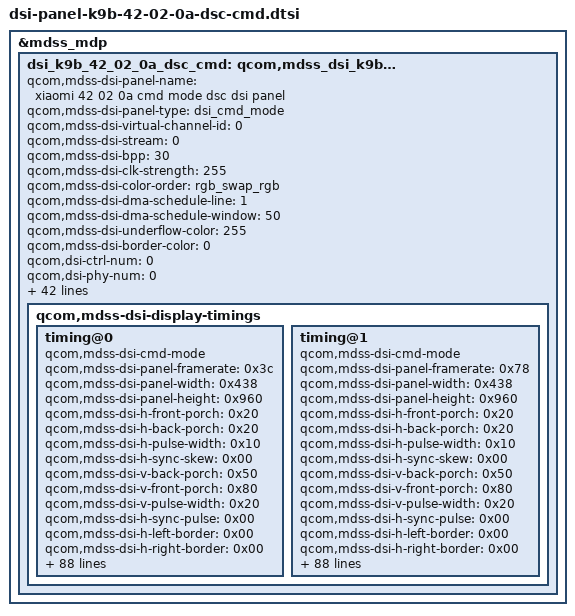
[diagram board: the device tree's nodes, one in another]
&mdss_mdp {
	dsi_k9b_42_02_0a_dsc_cmd: qcom,mdss_dsi_k9b_42_02_0a_dsc_cmd {
		qcom,mdss-dsi-panel-name = "xiaomi 42 02 0a cmd mode dsc dsi panel";
		qcom,mdss-dsi-panel-type = "dsi_cmd_mode";
		qcom,mdss-dsi-virtual-channel-id = <0>;
		qcom,mdss-dsi-stream = <0>;
		qcom,mdss-dsi-bpp = <30>;
		qcom,mdss-dsi-clk-strength = <255>;
		qcom,mdss-dsi-color-order = "rgb_swap_rgb";
		qcom,mdss-dsi-dma-schedule-line = <1>;
		qcom,mdss-dsi-dma-schedule-window = <50>;
		qcom,mdss-dsi-underflow-color = <255>;
		qcom,mdss-dsi-border-color = <0>;

		qcom,dsi-ctrl-num = <0>;
		qcom,dsi-phy-num = <0>;

		qcom,mdss-dsi-traffic-mode = "burst_mode";
		qcom,mdss-dsi-lane-map = "lane_map_0123";
		qcom,mdss-dsi-bllp-eof-power-mode;
		qcom,mdss-dsi-bllp-power-mode;
		qcom,mdss-dsi-lane-0-state;
		qcom,mdss-dsi-lane-1-state;
		qcom,mdss-dsi-lane-2-state;
		qcom,mdss-dsi-lane-3-state;
		qcom,mdss-dsi-dma-trigger = "trigger_sw";
		qcom,mdss-dsi-factory-bl-max-level = <2047>;
		qcom,mdss-dsi-mdp-trigger = "none";
		qcom,mdss-dsi-reset-sequence =  <1 11>, <0 1>, <1 11>;
		qcom,mdss-factory-brightness-max-level = <2047>;
		qcom,mdss-pan-physical-height-dimension = <1517>;
		qcom,mdss-pan-physical-width-dimension = <683>;
		qcom,mdss-dsi-te-pin-select = <1>;
		qcom,mdss-dsi-wr-mem-start = <0x2c>;
		qcom,mdss-dsi-wr-mem-continue = <0x3c>;
		qcom,mdss-dsi-te-dcs-command = <1>;
		qcom,mdss-dsi-te-check-enable;
		qcom,mdss-dsi-te-using-te-pin;
		qcom,mdss-dsi-tx-eot-append;
		qcom,mdss-dsi-lp11-init;

		qcom,mdss-dsi-bl-inverted-dbv;
		qcom,bl-update-flag = "delay_until_first_frame";
		qcom,mdss-dsi-panel-blackness-level = <3230>;
		qcom,mdss-dsi-panel-hdr-color-primaries = <0x38a4 0x3c8c 0x7d00 0x4268 0x3c8c 0x7530 0x1f40 0xbb8>;
		qcom,mdss-dsi-panel-hdr-enabled;
		qcom,mdss-dsi-panel-mode-switch;

		qcom,mdss-dsi-display-timings {
			timing@0{
				qcom,mdss-dsi-cmd-mode;
				qcom,mdss-dsi-panel-framerate = <60>;
				qcom,mdss-dsi-panel-width = <1080>;
				qcom,mdss-dsi-panel-height = <2400>;
				qcom,mdss-dsi-h-front-porch = <32>;
				qcom,mdss-dsi-h-back-porch = <32>;
				qcom,mdss-dsi-h-pulse-width = <16>;
				qcom,mdss-dsi-h-sync-skew = <0>;
				qcom,mdss-dsi-v-back-porch = <8>;
				qcom,mdss-dsi-v-front-porch = <1212>;
				qcom,mdss-dsi-v-pulse-width = <4>;
				qcom,mdss-dsi-h-sync-pulse = <0>;
				qcom,mdss-dsi-h-left-border = <0>;
				qcom,mdss-dsi-h-right-border = <0>;
				qcom,mdss-dsi-v-top-border = <0>;
				qcom,mdss-dsi-v-bottom-border = <0>;
				qcom,mdss-dsi-panel-clockrate = <682000000>;
				qcom,mdss-dsi-panel-jitter = <0x5 0x1>;
				qcom,mdss-mdp-transfer-time-us = <9500>;
				qcom,mdss-dsi-on-command = [
					/* Command Mode */
					39 00 00 00 00 00 06 F0 55 AA 52 08 00
					39 01 00 00 00 00 03 C0 52 F3
					/* ESD/MIPI Error Flag, Low when Error Happen */
					39 00 00 00 00 00 06 F0 55 AA 52 08 00
					39 00 00 00 00 00 05 BE 0E 0B 14 13
					15 00 00 00 00 00 02 6F 05
					15 01 00 00 00 00 02 BE 8A
					/* Round Corner OFF */
					39 00 00 00 00 00 06 F0 55 AA 52 08 07
					39 01 00 00 00 00 03 C0 00 02
					/* VESA ON */
					39 00 00 00 00 00 06 F0 55 AA 52 08 01	// Set page 1
					39 00 00 00 00 00 04 D1 07 00 04
					39 00 00 00 00 00 05 B3 12 12 22 22
					39 00 00 00 00 00 05 B4 12 12 22 22
					15 01 00 00 00 00 02 90 01
					/* Choose VESA Edition */
					39 00 00 00 00 00 13 91
						AB 28 00 0C C2 00 03 1C 01 7E
						00 0F 08 BB 04 3D 10 F0	// DSC Setting
					15 00 00 00 00 00 02 03 01
					39 00 00 00 00 00 05 51 00 00 00 00	// Normal Mode
					15 00 00 00 00 00 02 53 20
					15 00 00 00 00 00 02 35 00	// TE ON
					39 00 00 00 00 00 05 2A 00 00 04 37
					39 00 00 00 00 00 05 2B 00 00 09 5F
					15 01 00 00 00 00 02 2F 02	// 60Hz
					/* OSC=109.2MHz */
					39 00 00 00 00 00 05 FF AA 55 A5 81
					15 00 00 00 00 00 02 6F 0F
					39 01 00 00 00 00 03 FD 01 5A
					/* Demura Gain */
					39 00 00 00 00 00 05 FF AA 55 A5 80
					39 00 00 00 00 00 04 C0 76 F3 C1
					39 00 00 00 00 00 06 F0 55 AA 52 08 04
					15 00 00 00 00 00 02 C2 14
					15 00 00 00 00 00 02 B1 02
					15 00 00 00 00 00 02 B2 40
					15 00 00 00 00 00 02 6F 04
					39 00 00 00 00 00 04 B2 09 E4 00
					15 00 00 00 00 00 02 6F 0A
					39 00 00 00 00 00 04 B2 09 E3 40
					15 00 00 00 00 00 02 CB A4
					39 01 00 00 00 00 05 D0 00 80 00 20
					/* AOD Demura */
					15 00 00 00 00 00 02 B0 01
					39 00 00 00 00 00 06 F0 55 AA 52 08 00
					15 00 00 00 00 00 02 6F 01
					15 01 00 00 00 00 02 C0 B3
					/* AOD Demura End */
					39 00 00 00 00 00 06 F0 55 AA 52 08 04
					15 00 00 00 00 00 02 6F 04
					15 01 00 00 00 00 02 D0 01
					39 00 00 00 00 00 06 F0 55 AA 52 08 00
					15 00 00 00 00 00 02 6F 08
					15 00 00 00 00 00 02 C0 55
					15 01 00 00 00 00 02 8B 10
					39 00 00 00 00 00 06 F0 55 AA 52 08 04
					15 00 00 00 00 00 02 6F 01
					39 01 00 00 00 00 10 CB
						10 20 30 40 80 00 08 00 F6 01
						C2 04 CC 07 FF
					/* 90Hz Gain */
					39 01 00 00 00 00 4C D2
						E0 50 36 2C 27 B0 56 48 34 2E
						A0 60 51 40 32 90 69 59 47 40
						90 73 60 4C 40 E0 50 36 2C 27
						B0 56 48 34 2E A0 60 51 40 32
						90 69 59 47 40 90 73 60 4C 40
						E0 50 36 2C 27 B0 56 48 34 2E
						A0 60 51 40 32 90 69 59 47 40
						90 73 60 4C 40
					/* 60Hz Gain */
					39 01 00 00 00 00 4C D4
						C0 A0 90 90 90 36 39 40 50 60
						25 2C 38 46 5A 24 2B 35 44 48
						13 2A 32 42 42 C0 A0 90 90 90
						36 39 40 50 60 25 2C 38 46 5A
						24 2B 35 44 48 13 2A 32 42 42
						C0 A0 90 90 90 36 39 40 50 60
						25 2C 38 46 5A 24 2B 35 44 48
						13 2A 32 42 42
					/* Demura DC */
					39 01 00 00 00 00 4C D9
						40 40 40 40 40 40 40 40 40 40
						40 40 40 40 40 40 40 40 40 40
						40 40 40 40 40 40 40 40 40 40
						40 40 40 40 40 40 40 40 40 40
						40 40 40 40 40 40 40 40 40 40
						40 40 40 40 40 40 40 40 40 40
						40 40 40 40 40 40 40 40 40 40
						40 40 40 40 40
					/* FCON code */
					39 00 00 00 00 00 06 F0 55 AA 52 08 00
					/* FCON = 1 (90hz) */
					39 00 00 00 00 00 09 BA 01 E9 00 10 00 30 00 01
					/* FCON = 2 (60hz) */
					15 00 00 00 00 00 02 6F 08
					39 00 00 00 00 00 09 BA 01 E9 00 10 04 D0 00 01	// PWM 60&90Hz
					/* FCON = 3 (DC=60hz) */
					15 00 00 00 00 00 02 6F 10
					39 00 00 00 00 00 09 BA 01 E9 00 10 04 D0 00 01
					39 00 00 00 00 00 03 B2 50 63
					15 00 00 00 00 00 02 6F 05
					39 00 00 00 00 00 03 B2 30 30	// Dimming speed: 48 DBV/Frame
					15 00 00 00 00 00 02 6F 0F
					39 00 00 00 00 00 03 B2 20 50
					/* EM_DT_0_HFR1 ~EM_DT_0_HFR18 (60hz) */
					15 00 00 00 00 00 02 6F 2C
					39 00 00 00 00 00 27 B3
						0E 40 0D F5 0C D2 0C D2 0C 3C
						0C 3C 0A 51 0A 51 06 44 06 44
						00 6A 00 6A 00 6A 00 6A 00 6A
						00 6A 00 6A 00 6A 00 6A
					/* EM_DT_0~EM_DT_18 (90hz) */
					39 01 00 00 00 00 27 B4
						09 A0 09 6E 08 A9 08 A9 08 44
						08 44 06 F8 06 F8 04 3C 04 3C
						00 48 00 48 00 48 00 48 00 48
						00 48 00 48 00 48 00 48
					/* Sleep Out */
					05 01 00 00 78 00 02 11 00
					/* Display On */
					05 01 00 00 10 00 02 29 00];
				qcom,mdss-dsi-off-command = [
					05 01 00 00 00 00 02 28 00
					05 01 00 00 78 00 02 10 00];
				qcom,mdss-dsi-on-command-state = "dsi_lp_mode";
				qcom,mdss-dsi-off-command-state = "dsi_lp_mode";

				qcom,mdss-dsi-timing-switch-command = [
					15 01 00 00 00 00 02 2F 02];
				qcom,mdss-dsi-timing-switch-command-state = "dsi_lp_mode";

				qcom,mdss-dsi-nolp-command = [
					15 00 00 00 00 00 02 65 00
					05 00 00 00 00 00 01 38
					05 00 00 00 00 00 01 2C
					15 01 00 00 00 00 02 2F 02];
				qcom,mdss-dsi-nolp-command-state = "dsi_lp_mode";

				qcom,compression-mode = "dsc";
				qcom,mdss-dsc-version = <0x11>;
				qcom,mdss-dsc-scr-version = <0x0>;
				qcom,mdss-dsc-slice-height = <12>;
				qcom,mdss-dsc-slice-width = <1080>;
				qcom,mdss-dsc-slice-per-pkt = <1>;
				qcom,mdss-dsc-bit-per-component = <10>;
				qcom,mdss-dsc-bit-per-pixel = <8>;
				qcom,mdss-dsc-block-prediction-enable;
			};

			timing@1{
				qcom,mdss-dsi-cmd-mode;
				qcom,mdss-dsi-panel-framerate = <90>;
				qcom,mdss-dsi-panel-width = <1080>;
				qcom,mdss-dsi-panel-height = <2400>;
				qcom,mdss-dsi-h-front-porch = <16>;
				qcom,mdss-dsi-h-back-porch = <8>;
				qcom,mdss-dsi-h-pulse-width = <8>;
				qcom,mdss-dsi-h-sync-skew = <0>;
				qcom,mdss-dsi-v-back-porch = <8>;
				qcom,mdss-dsi-v-front-porch = <4>;
				qcom,mdss-dsi-v-pulse-width = <4>;
				qcom,mdss-dsi-h-sync-pulse = <0>;
				qcom,mdss-dsi-h-left-border = <0>;
				qcom,mdss-dsi-h-right-border = <0>;
				qcom,mdss-dsi-v-top-border = <0>;
				qcom,mdss-dsi-v-bottom-border = <0>;
				qcom,mdss-dsi-panel-clockrate = <682000000>;
				qcom,mdss-dsi-panel-jitter = <0x5 0x1>;
				qcom,mdss-mdp-transfer-time-us = <9500>;
				qcom,mdss-dsi-on-command = [
					/* Command Mode */
					39 00 00 00 00 00 06 F0 55 AA 52 08 00
					39 01 00 00 00 00 03 C0 52 F3
					/* ESD/MIPI Error Flag, Low when Error Happen */
					39 00 00 00 00 00 06 F0 55 AA 52 08 00
					39 00 00 00 00 00 05 BE 0E 0B 14 13
					15 00 00 00 00 00 02 6F 05
					15 01 00 00 00 00 02 BE 8A
					/* Round Corner OFF */
					39 00 00 00 00 00 06 F0 55 AA 52 08 07
					39 01 00 00 00 00 03 C0 00 02
					/* VESA ON */
					39 00 00 00 00 00 06 F0 55 AA 52 08 01	// Set page 1
					39 00 00 00 00 00 04 D1 07 00 04
					39 00 00 00 00 00 05 B3 12 12 22 22
					39 00 00 00 00 00 05 B4 12 12 22 22
					15 01 00 00 00 00 02 90 01
					/* Choose VESA Edition */
					39 00 00 00 00 00 13 91
						AB 28 00 0C C2 00 03 1C 01 7E
						00 0F 08 BB 04 3D 10 F0	// DSC Setting
					15 00 00 00 00 00 02 03 01
					39 00 00 00 00 00 05 51 00 00 00 00	// Normal Mode
					15 00 00 00 00 00 02 53 20
					15 00 00 00 00 00 02 35 00	// TE ON
					39 00 00 00 00 00 05 2A 00 00 04 37
					39 00 00 00 00 00 05 2B 00 00 09 5F
					15 01 00 00 00 00 02 2F 01	// 90Hz
					/* OSC=109.2MHz */
					39 00 00 00 00 00 05 FF AA 55 A5 81
					15 00 00 00 00 00 02 6F 0F
					39 01 00 00 00 00 03 FD 01 5A
					/* Demura Gain */
					39 00 00 00 00 00 05 FF AA 55 A5 80
					39 01 00 00 00 00 04 C0 76 F3 C1
					39 00 00 00 00 00 06 F0 55 AA 52 08 04
					15 00 00 00 00 00 02 C2 14
					15 00 00 00 00 00 02 B1 02
					15 00 00 00 00 00 02 B2 40
					15 00 00 00 00 00 02 6F 04
					39 00 00 00 00 00 04 B2 09 E4 00
					15 00 00 00 00 00 02 6F 0A
					39 00 00 00 00 00 04 B2 09 E3 40
					15 00 00 00 00 00 02 CB A4
					39 01 00 00 00 00 05 D0 00 80 00 20
					/* AOD Demura */
					15 00 00 00 00 00 02 B0 01
					39 00 00 00 00 00 06 F0 55 AA 52 08 00
					15 00 00 00 00 00 02 6F 01
					15 01 00 00 00 00 02 C0 B3
					/* AOD Demura End */
					39 00 00 00 00 00 06 F0 55 AA 52 08 04
					15 00 00 00 00 00 02 6F 04
					15 01 00 00 00 00 02 D0 01
					39 00 00 00 00 00 06 F0 55 AA 52 08 00
					15 00 00 00 00 00 02 6F 08
					15 00 00 00 00 00 02 C0 55
					15 01 00 00 00 00 02 8B 10
					39 00 00 00 00 00 06 F0 55 AA 52 08 04
					15 00 00 00 00 00 02 6F 01
					39 01 00 00 00 00 10 CB
						10 20 30 40 80 00 08 00 F6 01
						C2 04 CC 07 FF
					/* 90Hz Gain */
					39 01 00 00 00 00 4C D2
						E0 50 36 2C 27 B0 56 48 34 2E
						A0 60 51 40 32 90 69 59 47 40
						90 73 60 4C 40 E0 50 36 2C 27
						B0 56 48 34 2E A0 60 51 40 32
						90 69 59 47 40 90 73 60 4C 40
						E0 50 36 2C 27 B0 56 48 34 2E
						A0 60 51 40 32 90 69 59 47 40
						90 73 60 4C 40
					/* 60Hz Gain */
					39 01 00 00 00 00 4C D4
						C0 A0 90 90 90 36 39 40 50 60
						25 2C 38 46 5A 24 2B 35 44 48
						13 2A 32 42 42 C0 A0 90 90 90
						36 39 40 50 60 25 2C 38 46 5A
						24 2B 35 44 48 13 2A 32 42 42
						C0 A0 90 90 90 36 39 40 50 60
						25 2C 38 46 5A 24 2B 35 44 48
						13 2A 32 42 42
					/* Demura DC */
					39 01 00 00 00 00 4C D9
						40 40 40 40 40 40 40 40 40 40
						40 40 40 40 40 40 40 40 40 40
						40 40 40 40 40 40 40 40 40 40
						40 40 40 40 40 40 40 40 40 40
						40 40 40 40 40 40 40 40 40 40
						40 40 40 40 40 40 40 40 40 40
						40 40 40 40 40 40 40 40 40 40
						40 40 40 40 40
					/* FCON code */
					39 00 00 00 00 00 06 F0 55 AA 52 08 00
					/* FCON = 1 (90hz) */
					39 00 00 00 00 00 09 BA 01 E9 00 10 00 30 00 01
					/* FCON = 2 (60hz) */
					15 00 00 00 00 00 02 6F 08
					39 00 00 00 00 00 09 BA 01 E9 00 10 04 D0 00 01	// PWM 60&90Hz
					/* FCON = 3 (DC=60hz) */
					15 00 00 00 00 00 02 6F 10
					39 00 00 00 00 00 09 BA 01 E9 00 10 04 D0 00 01
					39 00 00 00 00 00 03 B2 50 63
					15 00 00 00 00 00 02 6F 05
					39 00 00 00 00 00 03 B2 20 20	// Dimming speed: 32 DBV/Frame
					15 00 00 00 00 00 02 6F 0F
					39 00 00 00 00 00 03 B2 20 50
					/* EM_DT_0_HFR1 ~EM_DT_0_HFR18 (60hz) */
					15 00 00 00 00 00 02 6F 2C
					39 00 00 00 00 00 27 B3
						0E 40 0D F5 0C D2 0C D2 0C 3C
						0C 3C 0A 51 0A 51 06 44 06 44
						00 6A 00 6A 00 6A 00 6A 00 6A
						00 6A 00 6A 00 6A 00 6A
					/* EM_DT_0~EM_DT_18 (90hz) */
					39 01 00 00 00 00 27 B4
						09 A0 09 6E 08 A9 08 A9 08 44
						08 44 06 F8 06 F8 04 3C 04 3C
						00 48 00 48 00 48 00 48 00 48
						00 48 00 48 00 48 00 48
					/* Sleep Out */
					05 01 00 00 8C 00 02 11 00
					/* Display On */
					05 01 00 00 10 00 02 29 00];
				qcom,mdss-dsi-off-command = [
					05 01 00 00 00 00 02 28 00
					05 01 00 00 78 00 02 10 00];
				qcom,mdss-dsi-on-command-state = "dsi_lp_mode";
				qcom,mdss-dsi-off-command-state = "dsi_lp_mode";

				qcom,mdss-dsi-timing-switch-command = [
					15 01 00 00 00 00 02 2F 01];
				qcom,mdss-dsi-timing-switch-command-state = "dsi_lp_mode";

				qcom,mdss-dsi-nolp-command = [
					15 00 00 00 00 00 02 65 00
					05 00 00 00 00 00 01 38
					05 00 00 00 00 00 01 2C
					15 01 00 00 00 00 02 2F 01];
				qcom,mdss-dsi-nolp-command-state = "dsi_lp_mode";

				qcom,compression-mode = "dsc";
				qcom,mdss-dsc-version = <0x11>;
				qcom,mdss-dsc-scr-version = <0x0>;
				qcom,mdss-dsc-slice-height = <12>;
				qcom,mdss-dsc-slice-width = <1080>;
				qcom,mdss-dsc-slice-per-pkt = <1>;
				qcom,mdss-dsc-bit-per-component = <10>;
				qcom,mdss-dsc-bit-per-pixel = <8>;
				qcom,mdss-dsc-block-prediction-enable;
			};
		};
	};
};

&dsi_k9b_42_02_0a_dsc_cmd {
	mi,panel-id = <0x4b3942 0x420200>;
	mi,hbm-51-ctl-flag;
	mi,hbm-off-51-index = <0>;
//	mi,hbm-on-51-index = <1>;
	mi,hbm-bl-min-level = <3>;
	mi,hbm-bl-max-level = <2045>;
	mi,hbm-fod-off-51-index = <0x00>;
	mi,local-hbm-enabled;
	mi,local-hbm-off-to-hbm-51-index = <0>;
	mi,local-hbm-off-to-normal-51-index = <0>;
	mi,local-hbm-on-87-index = <23>;
	mi,mdss-dsi-panel-dc-type = <0>;
//	mi,thermal-dimming-flag;
//	mi,timming-switch-wait-for-te-flag;
	qcom,mdss-dsi-panel-peak-brightness = <4200000>;

	qcom,mdss-dsi-display-timings {
		timing@0 {
			mi,mdss-dsc-panel-id = <0x4b3942 0x420200>;
			mi,mdss-dsi-dc-off-command = [39 01 00 00 00 00 06 f0 55 aa 52 08 00 39 00 00 00 00 00 02 b2 18 39 00 00 00 00 00 02 6f 0f 39 00 00 00 00 00 04 b2 30 20 31 47 21 47 20 00 39 00 00 00 00 00 25 b3 00 08 00 18 00 18 00 31 00 31 00 62 00 62 00 c0 00 c0 01 32 01 32 01 47 01 47 03 33 03 33 07 ff 07 ff 0f ff];
			mi,mdss-dsi-dc-off-command-state = "dsi_lp_mode";
			mi,mdss-dsi-dc-on-command = [39 01 00 00 00 00 06 f0 55 aa 52 08 00 39 00 00 00 00 00 02 b2 98 39 00 00 00 00 00 02 6f 0f 39 00 00 00 00 00 09 b2 00 00 01 47 01 47 00 00 39 00 00 00 00 00 25 b3 00 00 00 00 00 00 00 00 00 00 00 00 00 00 00 00 00 00 00 00 00 00 00 00 00 00 00 00 00 00 00 00 07 ff 0f ff 39 00 00 00 00 00 02 6f ac 39 00 00 00 00 00 47 b2 00 00 01 0a 01 6c 01 b6 01 f3 02 28 02 58 02 84 02 ac 02 d2 02 f5 03 17 03 37 04 e0 06 09 06 fa 07 c9 08 81 09 28 09 c1 0a 51 0a d7 0b 56 0b cf 0c 42 0c b0 0d 1a 0d 80 0d e3 0e 42 0e 9f 0e f9 0f 50 0f a5 0f ff 39 00 00 00 00 00 02 6f 52 39 01 00 00 00 00 45 b3 00 05 00 0a 00 0f 00 14 00 19 00 1e 00 23 00 28 00 2d 00 32 00 37 00 3c 00 96 00 f0 01 4a 01 a4 01 fe 02 58 02 b2 03 0c 03 66 03 c0 04 1a 04 74 04 ce 05 28 05 82 05 dc 06 36 06 90 06 ea 07 44 07 9e 07 ff];
			mi,mdss-dsi-dc-on-command-state = "dsi_lp_mode";
			mi,mdss-dsi-dimmingoff-command = [39 01 00 00 00 00 02 53 20];
			mi,mdss-dsi-dimmingoff-command-state = "dsi_hs_mode";
			mi,mdss-dsi-dimmingon-command = [39 01 00 00 00 00 02 53 28];
			mi,mdss-dsi-dimmingon-command-state = "dsi_hs_mode";
			mi,mdss-dsi-doze-hbm-command = <0x15010000 0x22f 0x1390100 0x06 0xf055aa52 0x8083900 0x00 0x26f0739 0x00 0x5b900 0x2439 0x1000000 0x6f055 0xaa520800 0x15010000 0x2b2 0x8050100 0x140002 0x39001501 0x00 0x2650105 0x1000000 0x22c00 0x39010000 0x551 0x7ff0fff>;
			mi,mdss-dsi-doze-hbm-command-state = "dsi_lp_mode";
			mi,mdss-dsi-doze-lbm-command = <0x15010000 0x22f 0x1390100 0x06 0xf055aa52 0x8083900 0x00 0x26f0739 0x00 0x5b900 0x2439 0x1000000 0x6f055 0xaa520800 0x15010000 0x2b2 0x8050100 0x140002 0x39001501 0x00 0x2650105 0x1000000 0x22c00 0x39010000 0x551 0x7ff0155>;
			mi,mdss-dsi-doze-lbm-command-state = "dsi_lp_mode";
			mi,mdss-dsi-flat-mode-off-command = [39 01 00 00 00 00 06 f0 55 aa 52 08 08 39 01 00 00 00 00 02 b9 00];
			mi,mdss-dsi-flat-mode-off-command-state = "dsi_lp_mode";
			mi,mdss-dsi-flat-mode-on-command = [39 01 00 00 00 00 06 f0 55 aa 52 08 08 39 01 00 00 00 00 02 b9 01];
			mi,mdss-dsi-flat-mode-on-command-state = "dsi_lp_mode";
			mi,mdss-dsi-hbm-fod-off-command = <0x39000000 0x351 0x7ff3900 0x00 0x26f0239 0x1000000 0x28704>;
			mi,mdss-dsi-hbm-fod-off-command-state = "dsi_lp_mode";
			mi,mdss-dsi-hbm-fod-on-command = <0x39000000 0x351 0xfff3900 0x00 0x26f0239 0x1000000 0x28704>;
			mi,mdss-dsi-hbm-fod-on-command-state = "dsi_lp_mode";
			mi,mdss-dsi-hbm-off-command = [39 01 00 00 00 00 03 51 07 ff];
			mi,mdss-dsi-hbm-off-command-state = "dsi_lp_mode";
			mi,mdss-dsi-hbm-on-command = [39 01 00 00 00 00 03 51 0f ff];
			mi,mdss-dsi-hbm-on-command-state = "dsi_lp_mode";
			mi,mdss-dsi-local-hbm-normal-white-1000nit-command = [39 01 00 00 00 00 06 f0 55 aa 52 08 00 39 01 00 00 00 00 02 6f 29 39 01 00 00 00 00 02 d9 00 39 01 00 00 00 00 02 6f 01 39 01 00 00 00 00 02 d9 80 39 01 00 00 00 00 02 6f 07 39 01 00 00 00 00 03 b2 07 ff 39 01 00 00 00 00 02 6f 17 39 01 00 00 00 00 03 b2 0f ff 39 01 00 00 00 00 02 6f 1f 39 01 00 00 00 00 03 b2 00 50 39 01 00 00 00 00 06 f0 55 aa 52 08 02 39 00 00 00 00 00 02 6f 08 39 00 00 00 00 00 07 d0 0b 07 09 7b 0c 1d 39 00 00 00 00 00 06 f0 55 aa 52 08 07 39 00 00 00 00 00 02 c0 05 39 01 00 00 00 00 2c c9 21 00 14 40 14 40 00 00 3f f4 9c 00 3f f4 9c 00 80 01 9a 10 00 31 57 8d 31 9f d5 33 50 14 40 0f b8 b8 00 00 00 00 00 00 00 00 00 39 01 00 00 00 00 2c ca 27 00 14 40 14 40 00 00 00 00 00 00 3f f4 9c 00 80 00 00 00 00 31 a0 8d 31 e8 d5 33 50 00 00 03 48 b8 00 00 00 00 00 00 00 00 00 39 01 00 00 00 00 25 cb 2d 00 14 40 15 f9 00 00 3f f4 22 80 40 00 00 00 80 00 00 00 00 31 57 d6 41 a2 1e 33 10 00 00 0c b8 4b 00 00 39 01 00 00 00 00 2d cc 2b 00 14 40 12 99 00 00 00 00 00 00 40 00 00 00 ff fe 87 65 c0 31 a3 d6 41 e8 1e 33 3f ec 98 00 48 45 00 00 cc 00 00 00 00 00 00 00 39 01 00 00 00 00 02 53 20 39 00 00 00 00 00 05 88 02 1b 07 53 39 00 00 00 00 00 03 87 0f ff 39 00 00 00 00 00 03 51 0f ff 39 00 00 00 00 00 03 87 04 4e 39 00 00 00 00 00 02 6f 02 39 01 00 00 00 00 02 87 05];
			mi,mdss-dsi-local-hbm-normal-white-1000nit-command-state = "dsi_hs_mode";
			mi,mdss-dsi-local-hbm-off-to-hbm-command = <0x39010000 0x351 0x3900 0x00 0x26f0239 0x1000000 0x28704>;
			mi,mdss-dsi-local-hbm-off-to-hbm-command-state = "dsi_lp_mode";
			mi,mdss-dsi-local-hbm-off-to-normal-command = <0x39010000 0x351 0x3900 0x00 0x26f0239 0x1000000 0x28704>;
			mi,mdss-dsi-local-hbm-off-to-normal-command-state = "dsi_lp_mode";
			qcom,compression-mode = "dsc";
			qcom,default-topology-index = <0x00>;
			qcom,display-topology = <0x01 0x01 0x01>;
			qcom,mdss-dsc-bit-per-component = <0x0a>;
			qcom,mdss-dsc-bit-per-pixel = <0x08>;
			qcom,mdss-dsc-block-prediction-enable;
			qcom,mdss-dsc-scr-version = <0x00>;
			qcom,mdss-dsc-slice-height = <0x0c>;
			qcom,mdss-dsc-slice-per-pkt = <0x01>;
			qcom,mdss-dsc-slice-width = <0x438>;
			qcom,mdss-dsc-version = <0x11>;
			qcom,mdss-dsi-cmd-mode;
			qcom,mdss-dsi-h-back-porch = <0x20>;
			qcom,mdss-dsi-h-front-porch = <0x20>;
			qcom,mdss-dsi-h-left-border = <0x00>;
			qcom,mdss-dsi-h-pulse-width = <0x10>;
			qcom,mdss-dsi-h-right-border = <0x00>;
			qcom,mdss-dsi-h-sync-pulse = <0x00>;
			qcom,mdss-dsi-h-sync-skew = <0x00>;
			qcom,mdss-dsi-off-command = [05 01 00 00 14 00 02 28 00 05 01 00 00 50 00 02 10 00];
			qcom,mdss-dsi-off-command-state = "dsi_lp_mode";
			qcom,mdss-dsi-on-command = <0x15010000 0x290 0x1390100 0x13 0x91a92800 0xcc20003 0x1c017e00 0xf08bb04 0x3d10f015 0x1000000 0x20301 0x15010000 0x22c 0x150100 0x02 0x35003901 0x00 0x52a0000 0x4373901 0x00 0x52b0000 0x95f1501 0x00 0x2532839 0x1000000 0x35107 0xff150100 0x02 0x2f013901 0x00 0x6f055aa 0x52080139 0x1000000 0x8c38a 0x189d022 0x2000501 0x8000 0x2110005 0x1000010 0x22900>;
			qcom,mdss-dsi-on-command-state = "dsi_lp_mode";
			qcom,mdss-dsi-panel-clockrate = <0x18f96ec0>;
			qcom,mdss-dsi-panel-framerate = <0x3c>;
			qcom,mdss-dsi-panel-height = <0x960>;
			qcom,mdss-dsi-panel-jitter = <0x05 0x01>;
			qcom,mdss-dsi-panel-phy-timings = [00 18 06 06 21 20 06 06 04 02 04 00 15 16];
			qcom,mdss-dsi-panel-width = <0x438>;
			qcom,mdss-dsi-v-back-porch = <0x50>;
			qcom,mdss-dsi-v-bottom-border = <0x00>;
			qcom,mdss-dsi-v-front-porch = <0x80>;
			qcom,mdss-dsi-v-pulse-width = <0x20>;
			qcom,mdss-dsi-v-top-border = <0x00>;
			qcom,mdss-mdp-transfer-time-us = <0x36b0>;
		};

		timing@1{
			mi,mdss-dsc-panel-id = <0x4b3942 0x420200>;
			mi,mdss-dsi-dc-off-command = [39 01 00 00 00 00 06 f0 55 aa 52 08 00 39 00 00 00 00 00 02 b2 18 39 00 00 00 00 00 02 6f 0f 39 00 00 00 00 00 04 b2 30 20 31 47 21 47 20 00 39 00 00 00 00 00 25 b3 00 08 00 18 00 18 00 31 00 31 00 62 00 62 00 c0 00 c0 01 32 01 32 01 47 01 47 03 33 03 33 07 ff 07 ff 0f ff];
			mi,mdss-dsi-dc-off-command-state = "dsi_lp_mode";
			mi,mdss-dsi-dc-on-command = [39 01 00 00 00 00 06 f0 55 aa 52 08 00 39 00 00 00 00 00 02 b2 98 39 00 00 00 00 00 02 6f 0f 39 00 00 00 00 00 09 b2 00 00 01 47 01 47 00 00 39 00 00 00 00 00 25 b3 00 00 00 00 00 00 00 00 00 00 00 00 00 00 00 00 00 00 00 00 00 00 00 00 00 00 00 00 00 00 00 00 07 ff 0f ff 39 00 00 00 00 00 02 6f ac 39 00 00 00 00 00 47 b2 00 00 01 0a 01 6c 01 b6 01 f3 02 28 02 58 02 84 02 ac 02 d2 02 f5 03 17 03 37 04 e0 06 09 06 fa 07 c9 08 81 09 28 09 c1 0a 51 0a d7 0b 56 0b cf 0c 42 0c b0 0d 1a 0d 80 0d e3 0e 42 0e 9f 0e f9 0f 50 0f a5 0f ff 39 00 00 00 00 00 02 6f 52 39 01 00 00 00 00 45 b3 00 05 00 0a 00 0f 00 14 00 19 00 1e 00 23 00 28 00 2d 00 32 00 37 00 3c 00 96 00 f0 01 4a 01 a4 01 fe 02 58 02 b2 03 0c 03 66 03 c0 04 1a 04 74 04 ce 05 28 05 82 05 dc 06 36 06 90 06 ea 07 44 07 9e 07 ff];
			mi,mdss-dsi-dc-on-command-state = "dsi_lp_mode";
			mi,mdss-dsi-dimmingoff-command = [39 01 00 00 00 00 02 53 20];
			mi,mdss-dsi-dimmingoff-command-state = "dsi_hs_mode";
			mi,mdss-dsi-dimmingon-command = [39 01 00 00 00 00 02 53 28];
			mi,mdss-dsi-dimmingon-command-state = "dsi_hs_mode";
			mi,mdss-dsi-doze-hbm-command = <0x15010000 0x22f 0x1390100 0x06 0xf055aa52 0x8083900 0x00 0x26f0739 0x00 0x5b900 0x2439 0x1000000 0x6f055 0xaa520800 0x15010000 0x2b2 0x8050100 0x140002 0x39001501 0x00 0x2650105 0x1000000 0x22c00 0x39010000 0x551 0x7ff0fff>;
			mi,mdss-dsi-doze-hbm-command-state = "dsi_lp_mode";
			mi,mdss-dsi-doze-lbm-command = <0x15010000 0x22f 0x2390100 0x06 0xf055aa52 0x8083900 0x00 0x26f0739 0x00 0x5b900 0x2439 0x1000000 0x6f055 0xaa520800 0x15010000 0x2b2 0x8050100 0x140002 0x39001501 0x00 0x2650105 0x1000000 0x22c00 0x39010000 0x551 0x7ff0155>;
			mi,mdss-dsi-doze-lbm-command-state = "dsi_lp_mode";
			mi,mdss-dsi-flat-mode-off-command = [39 01 00 00 00 00 06 f0 55 aa 52 08 08 39 01 00 00 00 00 02 b9 00];
			mi,mdss-dsi-flat-mode-off-command-state = "dsi_lp_mode";
			mi,mdss-dsi-flat-mode-on-command = [39 01 00 00 00 00 06 f0 55 aa 52 08 08 39 01 00 00 00 00 02 b9 01];
			mi,mdss-dsi-flat-mode-on-command-state = "dsi_lp_mode";
			mi,mdss-dsi-hbm-fod-off-command = <0x39000000 0x351 0x7ff3900 0x00 0x26f0239 0x1000000 0x28704>;
			mi,mdss-dsi-hbm-fod-off-command-state = "dsi_lp_mode";
			mi,mdss-dsi-hbm-fod-on-command = <0x39000000 0x351 0xfff3900 0x00 0x26f0239 0x1000000 0x28704>;
			mi,mdss-dsi-hbm-fod-on-command-state = "dsi_lp_mode";
			mi,mdss-dsi-hbm-off-command = [39 01 00 00 00 00 03 51 07 ff];
			mi,mdss-dsi-hbm-off-command-state = "dsi_lp_mode";
			mi,mdss-dsi-hbm-on-command = [39 01 00 00 00 00 03 51 0f ff];
			mi,mdss-dsi-hbm-on-command-state = "dsi_lp_mode";
			mi,mdss-dsi-local-hbm-normal-white-1000nit-command = [39 01 00 00 00 00 06 f0 55 aa 52 08 00 39 01 00 00 00 00 02 6f 29 39 01 00 00 00 00 02 d9 00 39 01 00 00 00 00 02 6f 01 39 01 00 00 00 00 02 d9 80 39 01 00 00 00 00 02 6f 07 39 01 00 00 00 00 03 b2 07 ff 39 01 00 00 00 00 02 6f 17 39 01 00 00 00 00 03 b2 0f ff 39 01 00 00 00 00 02 6f 1f 39 01 00 00 00 00 03 b2 00 50 39 01 00 00 00 00 06 f0 55 aa 52 08 02 39 00 00 00 00 00 02 6f 08 39 00 00 00 00 00 07 d0 0b 07 09 7b 0c 1d 39 00 00 00 00 00 06 f0 55 aa 52 08 07 39 00 00 00 00 00 02 c0 05 39 01 00 00 00 00 2c c9 21 00 14 40 14 40 00 00 3f f4 9c 00 3f f4 9c 00 80 01 9a 10 00 31 57 8d 31 9f d5 33 50 14 40 0f b8 b8 00 00 00 00 00 00 00 00 00 39 01 00 00 00 00 2c ca 27 00 14 40 14 40 00 00 00 00 00 00 3f f4 9c 00 80 00 00 00 00 31 a0 8d 31 e8 d5 33 50 00 00 03 48 b8 00 00 00 00 00 00 00 00 00 39 01 00 00 00 00 25 cb 2d 00 14 40 15 f9 00 00 3f f4 22 80 40 00 00 00 80 00 00 00 00 31 57 d6 41 a2 1e 33 10 00 00 0c b8 4b 00 00 39 01 00 00 00 00 2d cc 2b 00 14 40 12 99 00 00 00 00 00 00 40 00 00 00 ff fe 87 65 c0 31 a3 d6 41 e8 1e 33 3f ec 98 00 48 45 00 00 cc 00 00 00 00 00 00 00 39 01 00 00 00 00 02 53 20 39 00 00 00 00 00 05 88 02 1b 07 53 39 00 00 00 00 00 03 87 0f ff 39 00 00 00 00 00 03 51 0f ff 39 00 00 00 00 00 03 87 04 4e 39 00 00 00 00 00 02 6f 02 39 01 00 00 00 00 02 87 05];
			mi,mdss-dsi-local-hbm-normal-white-1000nit-command-state = "dsi_hs_mode";
			mi,mdss-dsi-local-hbm-off-to-hbm-command = <0x39010000 0x351 0x3900 0x00 0x26f0239 0x1000000 0x28704>;
			mi,mdss-dsi-local-hbm-off-to-hbm-command-state = "dsi_lp_mode";
			mi,mdss-dsi-local-hbm-off-to-normal-command = <0x39010000 0x351 0x3900 0x00 0x26f0239 0x1000000 0x28704>;
			mi,mdss-dsi-local-hbm-off-to-normal-command-state = "dsi_lp_mode";
			qcom,compression-mode = "dsc";
			qcom,default-topology-index = <0x00>;
			qcom,display-topology = <0x01 0x01 0x01>;
			qcom,mdss-dsc-bit-per-component = <0x0a>;
			qcom,mdss-dsc-bit-per-pixel = <0x08>;
			qcom,mdss-dsc-block-prediction-enable;
			qcom,mdss-dsc-scr-version = <0x00>;
			qcom,mdss-dsc-slice-height = <0x0c>;
			qcom,mdss-dsc-slice-per-pkt = <0x01>;
			qcom,mdss-dsc-slice-width = <0x438>;
			qcom,mdss-dsc-version = <0x11>;
			qcom,mdss-dsi-cmd-mode;
			qcom,mdss-dsi-h-back-porch = <0x20>;
			qcom,mdss-dsi-h-front-porch = <0x20>;
			qcom,mdss-dsi-h-left-border = <0x00>;
			qcom,mdss-dsi-h-pulse-width = <0x10>;
			qcom,mdss-dsi-h-right-border = <0x00>;
			qcom,mdss-dsi-h-sync-pulse = <0x00>;
		        qcom,mdss-dsi-h-sync-skew = <0x00>;
			qcom,mdss-dsi-off-command = [05 01 00 00 14 00 02 28 00 05 01 00 00 50 00 02 10 00];
			qcom,mdss-dsi-off-command-state = "dsi_lp_mode";
			qcom,mdss-dsi-on-command = <0x15010000 0x290 0x1390100 0x13 0x91a92800 0xcc20003 0x1c017e00 0xf08bb04 0x3d10f015 0x1000000 0x20301 0x15010000 0x22c 0x150100 0x02 0x35003901 0x00 0x52a0000 0x4373901 0x00 0x52b0000 0x95f1501 0x00 0x2532839 0x1000000 0x35107 0xff150100 0x02 0x2f023901 0x00 0x6f055aa 0x52080139 0x1000000 0x8c394 0x18cd022 0x2000501 0x8000 0x2110005 0x1000010 0x22900>;
			qcom,mdss-dsi-on-command-state = "dsi_lp_mode";
			qcom,mdss-dsi-panel-clockrate = <0x31880dc0>;
			qcom,mdss-dsi-panel-framerate = <0x78>;
			qcom,mdss-dsi-panel-height = <0x960>;
			qcom,mdss-dsi-panel-jitter = <0x05 0x01>;
			qcom,mdss-dsi-panel-phy-timings = [00 18 06 06 21 20 06 06 04 02 04 00 15 16];
			qcom,mdss-dsi-panel-width = <0x438>;
			qcom,mdss-dsi-v-back-porch = <0x50>;
			qcom,mdss-dsi-v-bottom-border = <0x00>;
			qcom,mdss-dsi-v-front-porch = <0x80>;
			qcom,mdss-dsi-v-pulse-width = <0x20>;
			qcom,mdss-dsi-v-top-border = <0x00>;
			qcom,mdss-mdp-transfer-time-us = <0x1f40>;
		};
	};
};
